# V8M_Generic register map
Vendor: ARM Ltd.; Series: M; File version: 2020-08-22T15:13:24.354567-05:00
V8M-Generic core descriptions, generated from ARM Development studio
CPU: CM4 r0p0, little endian, vendor SysTick, 8 interrupt priority bits
Registers are 32-bit, read-write, no defined reset value unless marked. A register's access mark holds for its fields unless they carry their own. Offsets are from the block's base; lines under a group give offsets from that group; [hi:lo] are bit positions; {n}, {i} and the like mark numbered series; 'fields as' and 'values as' point back to an identical list; <NAME> marks a mode.

## Memory map
0xE000E004 ICB size 0xC — Interrupt Control Registers
0xE000E010 SYST size 0x10 — SysTick Control Registers
0xE000E100 NVIC blocks up to offset 0x304 — Nested Vectored Interrupt Controller
0xE000ED00 SCB size 0x90 — System Control Block
0xE000ED90 MPU blocks up to offset 0x38 — Memory protection Unit Control Registers
0xE000EDD0 SAU size 0x1C — Security Attribute Unit
0xE000EDF0 DCB blocks up to offset 0x1C — Debug Registers
0xE000EF00 SIG size 0x4 — Software Interrupt Control
0xE000EF34 FPE size 0x18 — Floating Point Control Registers
0xE000EF50 CM blocks up to offset 0x2C — Cache Maintenance Operations
0xE000EFB0 DIB blocks up to offset 0x50 — Identification Registers

## CM — Cache Maintenance Operations
Base 0xE000EF50
0x00 ICIALLU wo — Invalidate all instruction caches to PoU
  [31:0] Ignored — The value written to this field is ignored
0x08 ICIMVAU wo — Invalidate instruction cache line by address to PoU
  [31:0] ADDRESS
0x12 DCIMVAC wo — Invalidate data or unified cache line by address to PoC
  [31:0] ADDRESS
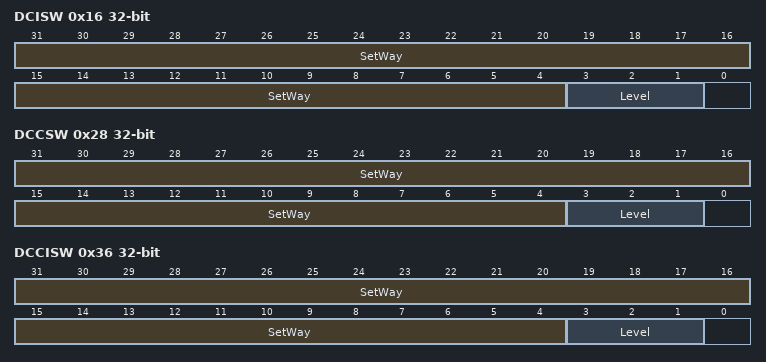
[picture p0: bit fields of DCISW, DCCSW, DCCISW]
0x16 DCISW wo — Invalidate data or unified cache line by set/way
  [31:4] SetWay — Cache set/way
  [3:1] Level — Cache level
0x20 DCCMVAU wo — Clean data or unified cache line by address to PoU
  [31:0] ADDRESS
0x24 DCCMVAC wo — Clean data or unified cache line by address to PoC
  [31:0] ADDRESS
0x28 DCCSW wo — Clean data or unified cache line by set/way
  [31:4] SetWay — Cache set/way
  [3:1] Level — Cache level
0x32 DCCIMVAC wo — Clean and invalidate data or unified cache line by address to PoC
  [31:0] ADDRESS
0x36 DCCISW wo — Clean and invalidate data or unified cache line by set/way
  [31:4] SetWay — Cache set/way
  [3:1] Level — Cache level
0x40 BPIALL wo — Invalidate all entries from branch predictors
  [31:0] Ignored

## ICB — Interrupt Control Registers
Base 0xE000E004
0x00 ICTR ro — Provides information about the interrupt controller
  [3:0] INTLINESNUM — Interrupt line set number
0x04 ACTLR — Provides IMPLEMENTATION DEFINED configuration and control options
0x08 CPPWR — Specifies whether coprocessors are permitted to enter a non-retentive power state
  [23] SUS11 — State UNKNOWN Secure only 11
  [22] SU11 — State UNKNOWN 11
  [21] SUS10 — State UNKNOWN Secure only 10
    0=The_SU10_field_is_accessible_from_both_Security_states; 1=The_SU10_field_is_only_accessible_from_the_Secure_state
  [20] SU10 — State UNKNOWN 10
    0=The_floating_point_state_is_not_permitted_to_become_UNKNOWN; 1=The_floating_point_state_is_permitted_to_become_UNKNOWN
  [n] SUS{n} (n=0..7) — State UNKNOWN Secure only {n}
    0=The_SUm_field_is_accessible_from_both_Security_states; 1=The_SUm_field_is_only_accessible_from_the_Secure_state
  [n] SU{n} (n=0..7) — State UNKNOWN {n}
    0=The_coprocessor_state_is_not_permitted_to_become_UNKNOWN; 1=The_coprocessor_state_is_permitted_to_become_UNKNOWN

## DIB — Identification Registers
Base 0xE000EFB0
0x00 DLAR wo — Provides CoreSight Software Lock control for the SCS, see the _ARM(R) CoreSight(TM) Architecture Specification_ for details
  [31:0] KEY — Lock Access control
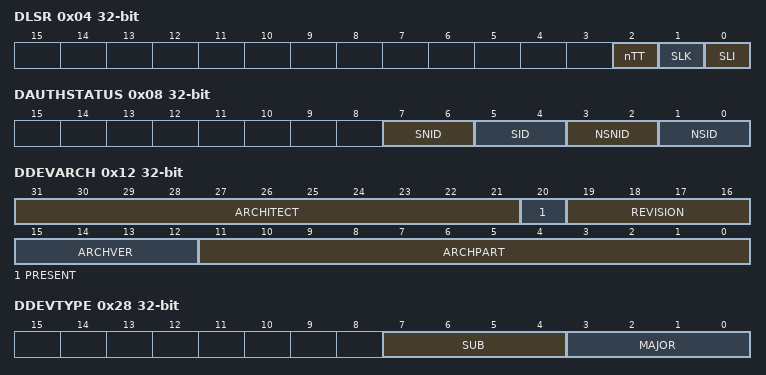
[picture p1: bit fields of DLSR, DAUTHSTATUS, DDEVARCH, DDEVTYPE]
0x04 DLSR ro — Provides CoreSight Software Lock status information for the SCS, see the _ARM(R) CoreSight(TM) Architecture Specification_ for details
  [2] nTT — Not thirty-two bit
  [1] SLK — Software Lock status
    0=Lock_clear; 1=Lock_set
  [0] SLI — Software Lock implemented
    0=Software_Lock_not_implemented_or_debugger_access; 1=Software_Lock_is_implemented_and_software_access
0x08 DAUTHSTATUS ro — Provides information about the state of the IMPLEMENTATION DEFINED authentication interface for debug
  [7:6] SNID — Secure Non-invasive Debug
    0=Security_Extension_not_implemented; 2=Security_Extension_implemented_and_Secure_non_invasive_debug_prohibited; 3=Security_Extension_implemented_and_Secure_non_invasive_debug_allowed
  [5:4] SID — Secure Invasive Debug
    0=Security_Extension_not_implemented; 2=Security_Extension_implemented_and_Secure_invasive_debug_prohibited; 3=Security_Extension_implemented_and_Secure_invasive_debug_allowed
  [3:2] NSNID — Non-secure Non-invasive Debug
    2=Non_secure_non_invasive_debug_prohibited; 3=Non_secure_non_invasive_debug_allowed
  [1:0] NSID — Non-secure Invasive Debug
    2=Non_secure_invasive_debug_prohibited; 3=Non_secure_invasive_debug_allowed
0x12 DDEVARCH ro — Provides CoreSight discovery information for the SCS
  [31:21] ARCHITECT
    0x23B=JEP106_continuation_code_0x4_ID_code_0x3B
  [20] PRESENT — DEVARCH Present
    1=DEVARCH_information_present
  [19:16] REVISION
    0=M_profile_debug_architecture_v3
  [15:12] ARCHVER — Architecture Version
    2=M_profile_debug_architecture_v3
  [11:0] ARCHPART — Architecture Part
    0xA04=M_profile_debug_architecture
0x28 DDEVTYPE ro — Provides CoreSight discovery information for the SCS
  [7:4] SUB — Sub-type
    0=Other
  [3:0] MAJOR — Major type
    0=Miscellaneous
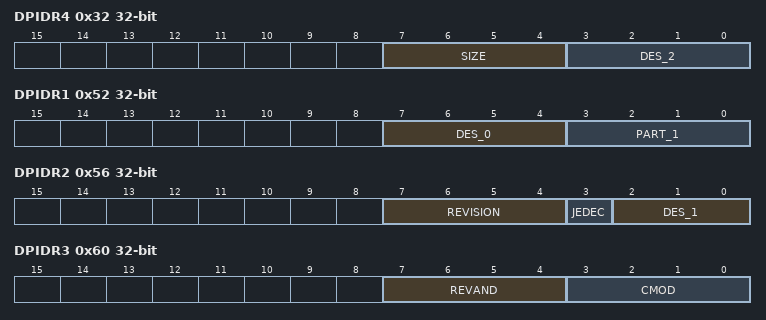
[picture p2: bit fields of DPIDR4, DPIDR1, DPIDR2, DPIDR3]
0x32 DPIDR4 ro — Provides CoreSight discovery information for the SCS
  [7:4] SIZE — 4KB count
  [3:0] DES_2 — JEP106 continuation code
0x36 DPIDR5 ro — Provides CoreSight discovery information for the SCS
0x40 DPIDR6 ro — Provides CoreSight discovery information for the SCS
0x44 DPIDR7 ro — Provides CoreSight discovery information for the SCS
0x48 DPIDR0 ro — Provides CoreSight discovery information for the SCS
  [7:0] PART_0 — Part number bits [7:0]
0x52 DPIDR1 ro — Provides CoreSight discovery information for the SCS
  [7:4] DES_0 — JEP106 identification code bits [3:0]
  [3:0] PART_1 — Part number bits [11:8]
0x56 DPIDR2 ro — Provides CoreSight discovery information for the SCS
  [7:4] REVISION — Component revision
  [3] JEDEC — JEDEC assignee value is used
  [2:0] DES_1 — JEP106 identification code bits [6:4]
0x60 DPIDR3 ro — Provides CoreSight discovery information for the SCS
  [7:4] REVAND
  [3:0] CMOD — Customer Modified
0x64 DCIDR0 ro — Provides CoreSight discovery information for the SCS
  [7:0] PRMBL_0 — CoreSight component identification preamble
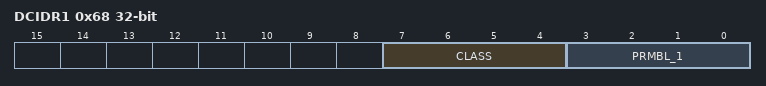
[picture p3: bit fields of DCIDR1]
0x68 DCIDR1 ro — Provides CoreSight discovery information for the SCS
  [7:4] CLASS — CoreSight component class
  [3:0] PRMBL_1 — CoreSight component identification preamble
0x72 DCIDR2 ro — Provides CoreSight discovery information for the SCS
  [7:0] PRMBL_2 — CoreSight component identification preamble
0x76 DCIDR3 ro — Provides CoreSight discovery information for the SCS
  [7:0] PRMBL_3 — CoreSight component identification preamble
